# Cortex_M35P register map
Vendor: ARM Ltd.; Series: M
CPU: CM35 r0p0, little endian, vendor SysTick, 8 interrupt priority bits
Registers are 32-bit, read-write, no defined reset value unless marked. A register's access mark holds for its fields unless they carry their own. Offsets are from the block's base; [hi:lo] are bit positions; {n}, {i} and the like mark numbered series; 'fields as' and 'values as' point back to an identical list.

## ICB — Interrupt Control Registers
Base 0xE000E004
0x00 ICTR ro
  [3:0] INTLINESNUM
0x04 ACTLR
0x08 CPPWR
  [23] SUS11, [22] SU11, [21] SUS10, [20] SU10, [n] SUS{n} (n=0..7), [n] SU{n} (n=0..7)

## DCB — Debug Registers
Base 0xE000EDF0
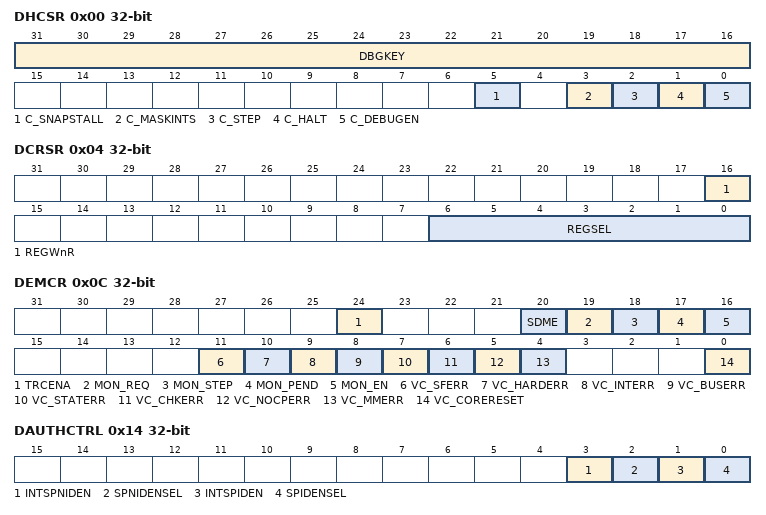
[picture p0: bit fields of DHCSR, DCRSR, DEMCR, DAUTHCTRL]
0x00 DHCSR
  [31:16] DBGKEY — Debug key
  [5] C_SNAPSTALL
  [3] C_MASKINTS
  [2] C_STEP
  [1] C_HALT
  [0] C_DEBUGEN
0x04 DCRSR wo
  [16] REGWnR, [6:0] REGSEL
0x08 DCRDR
  [31:0] DBGTMP
0x0C DEMCR ro
  [24] TRCENA, [20] SDME, [19] MON_REQ, [18] MON_STEP, [17] MON_PEND, [16] MON_EN, [11] VC_SFERR, [10] VC_HARDERR, [9] VC_INTERR, [8] VC_BUSERR, [7] VC_STATERR, [6] VC_CHKERR, [5] VC_NOCPERR, [4] VC_MMERR, [0] VC_CORERESET
0x14 DAUTHCTRL
  [3] INTSPNIDEN, [2] SPNIDENSEL, [1] INTSPIDEN, [0] SPIDENSEL
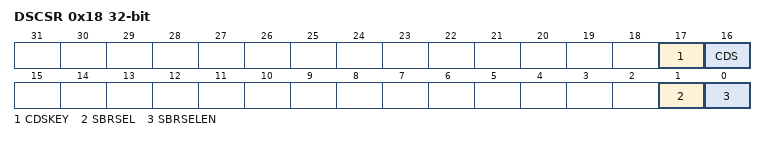
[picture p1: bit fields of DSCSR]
0x18 DSCSR ro
  [17] CDSKEY, [16] CDS, [1] SBRSEL, [0] SBRSELEN

## DIB — Identification Registers
Base 0xE000EFB0
0x00 DLAR wo
  [31:0] KEY
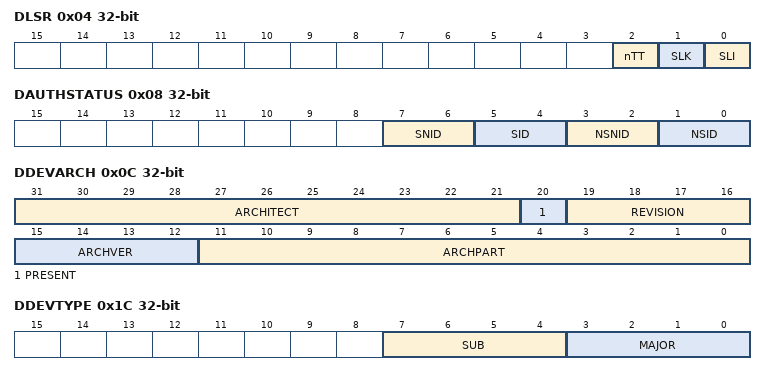
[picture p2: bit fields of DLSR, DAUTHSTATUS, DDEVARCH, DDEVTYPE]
0x04 DLSR ro
  [2] nTT, [1] SLK, [0] SLI
0x08 DAUTHSTATUS ro
  [7:6] SNID, [5:4] SID, [3:2] NSNID, [1:0] NSID
0x0C DDEVARCH ro
  [31:21] ARCHITECT, [20] PRESENT, [19:16] REVISION, [15:12] ARCHVER, [11:0] ARCHPART
0x1C DDEVTYPE ro
  [7:4] SUB — Sub-type
  [3:0] MAJOR
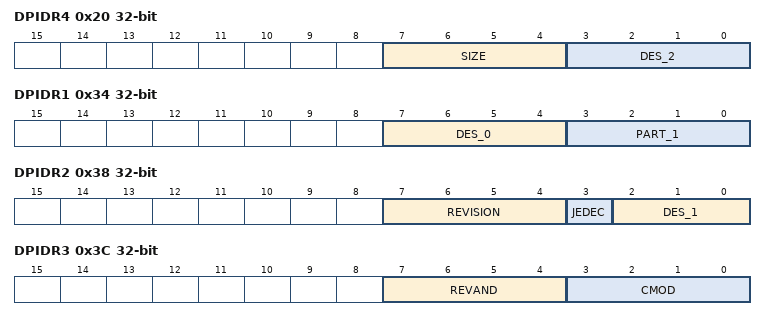
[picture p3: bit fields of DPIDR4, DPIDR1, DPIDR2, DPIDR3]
0x20 DPIDR4 ro
  [7:4] SIZE — 4KB count
  [3:0] DES_2
{0x10+4i} DPIDR{i} ro (i=5..7)
0x30 DPIDR0 ro
  [7:0] PART_0
0x34 DPIDR1 ro
  [7:4] DES_0, [3:0] PART_1
0x38 DPIDR2 ro
  [7:4] REVISION, [3] JEDEC, [2:0] DES_1
0x3C DPIDR3 ro
  [7:4] REVAND, [3:0] CMOD
0x40 DCIDR0 ro
  [7:0] PRMBL_0
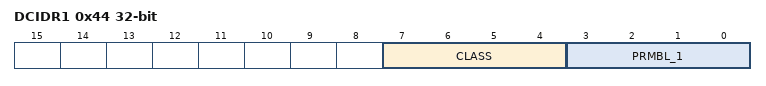
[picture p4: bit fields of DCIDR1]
0x44 DCIDR1 ro
  [7:4] CLASS, [3:0] PRMBL_1
0x48 DCIDR2 ro
  [7:0] PRMBL_2
0x4C DCIDR3 ro
  [7:0] PRMBL_3

## NVIC — Nested Vectored Interrupt Controller
Base 0xE000E100
0x00 NVIC_ISER{i} (i=0..15)
  [31:0] SETENA
0x00 NVIC_ISPR{i} (i=0..15)
  [31:0] SETPEND
0x80 NVIC_ICER{i} (i=0..15)
  [31:0] CLRENA
0x180 NVIC_ICPR{i} (i=0..15)
  [31:0] CLRPEND
0x200 NVIC_IABR{i} ro (i=0..15)
  [31:0] ACTIVE
0x280 NVIC_ITNS{i} (i=0..15)
  [31:0] ITNS
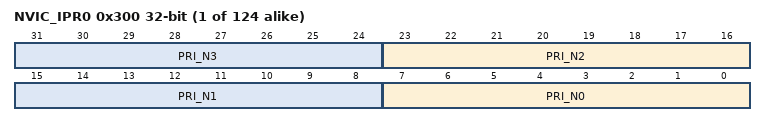
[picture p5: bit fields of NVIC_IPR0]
0x300 NVIC_IPR{i} (i=0..123)
  [8n+7:8n] PRI_N{n} (n=0..3)

## MPU — Memory protection Unit Control Registers
Base 0xE000ED90
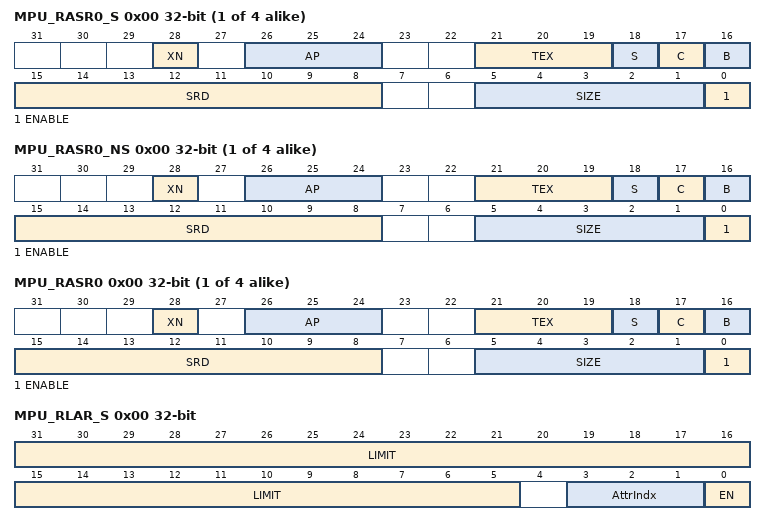
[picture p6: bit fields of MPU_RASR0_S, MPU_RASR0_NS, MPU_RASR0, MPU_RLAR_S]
0x00 MPU_RASR{i}_S (i=0..3)
  [28] XN, [26:24] AP, [21:19] TEX, [18] S, [17] C, [16] B, [15:8] SRD, [5:1] SIZE, [0] ENABLE
0x00 MPU_RASR{i}_NS (i=0..3)
  fields as MPU_RASR0_S
0x00 MPU_RASR{i} (i=0..3)
  fields as MPU_RASR0_S
0x00 MPU_RLAR_S
  [31:5] LIMIT
  [3:1] AttrIndx
  [0] EN — Enable
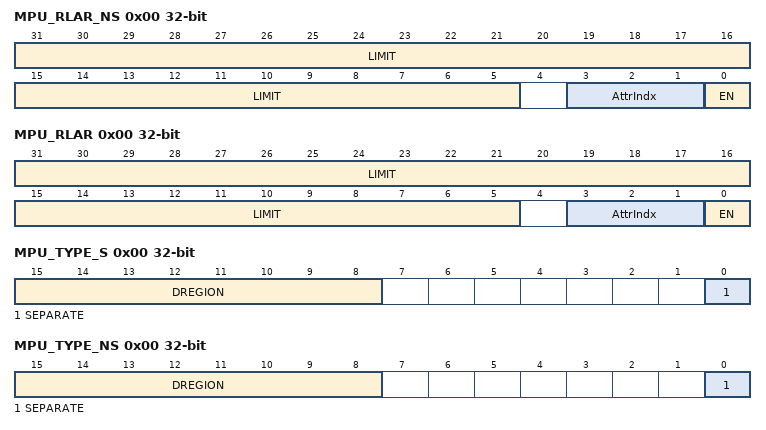
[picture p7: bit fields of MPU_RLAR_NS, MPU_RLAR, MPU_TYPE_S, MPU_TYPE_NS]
0x00 MPU_RLAR_NS
  [31:5] LIMIT
  [3:1] AttrIndx
  [0] EN — Enable
0x00 MPU_RLAR
  [31:5] LIMIT
  [3:1] AttrIndx
  [0] EN — Enable
0x00 MPU_TYPE_S ro
  [15:8] DREGION, [0] SEPARATE
0x00 MPU_TYPE_NS ro
  [15:8] DREGION, [0] SEPARATE
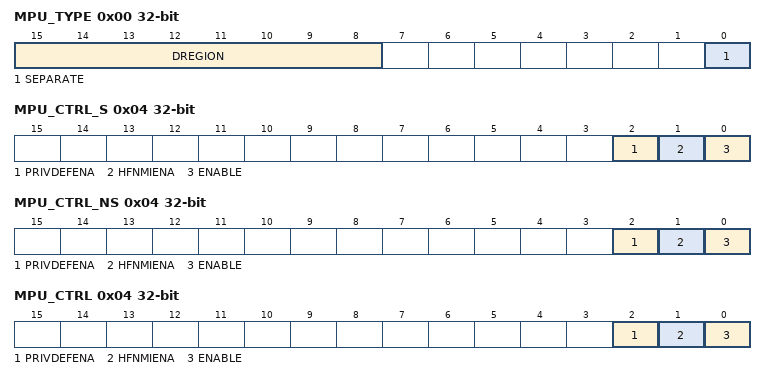
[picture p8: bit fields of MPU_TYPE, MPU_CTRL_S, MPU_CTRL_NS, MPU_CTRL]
0x00 MPU_TYPE ro
  [15:8] DREGION, [0] SEPARATE
0x04 MPU_CTRL_S
  [2] PRIVDEFENA, [1] HFNMIENA, [0] ENABLE
0x04 MPU_CTRL_NS
  [2] PRIVDEFENA, [1] HFNMIENA, [0] ENABLE
0x04 MPU_CTRL
  [2] PRIVDEFENA, [1] HFNMIENA, [0] ENABLE
0x08 MPU_RNR_S
  [7:0] REGION
0x08 MPU_RNR_NS
  [7:0] REGION
0x08 MPU_RNR
  [7:0] REGION
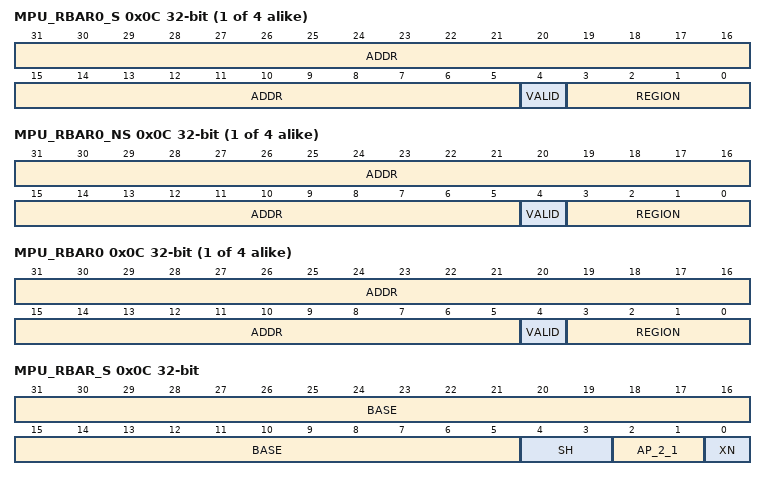
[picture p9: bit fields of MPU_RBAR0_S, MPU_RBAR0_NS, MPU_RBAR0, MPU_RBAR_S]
0x0C MPU_RBAR{i}_S (i=0..3)
  [31:5] ADDR, [4] VALID, [3:0] REGION
0x0C MPU_RBAR{i}_NS (i=0..3)
  [31:5] ADDR, [4] VALID, [3:0] REGION
0x0C MPU_RBAR{i} (i=0..3)
  [31:5] ADDR, [4] VALID, [3:0] REGION
0x0C MPU_RBAR_S
  [31:5] BASE, [4:3] SH, [2:1] AP_2_1, [0] XN
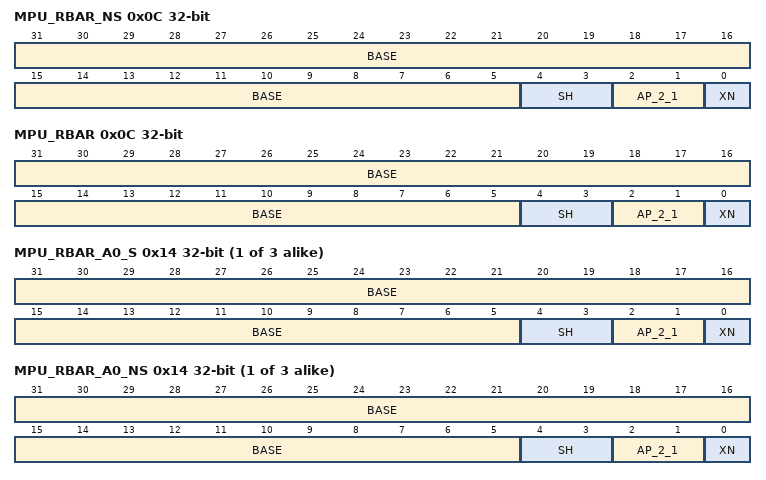
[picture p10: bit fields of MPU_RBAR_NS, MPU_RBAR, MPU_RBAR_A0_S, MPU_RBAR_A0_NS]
0x0C MPU_RBAR_NS
  [31:5] BASE, [4:3] SH, [2:1] AP_2_1, [0] XN
0x0C MPU_RBAR
  [31:5] BASE, [4:3] SH, [2:1] AP_2_1, [0] XN
0x14 MPU_RBAR_A{i}_S (i=0..2)
  [31:5] BASE, [4:3] SH, [2:1] AP_2_1, [0] XN
0x14 MPU_RBAR_A{i}_NS (i=0..2)
  [31:5] BASE, [4:3] SH, [2:1] AP_2_1, [0] XN
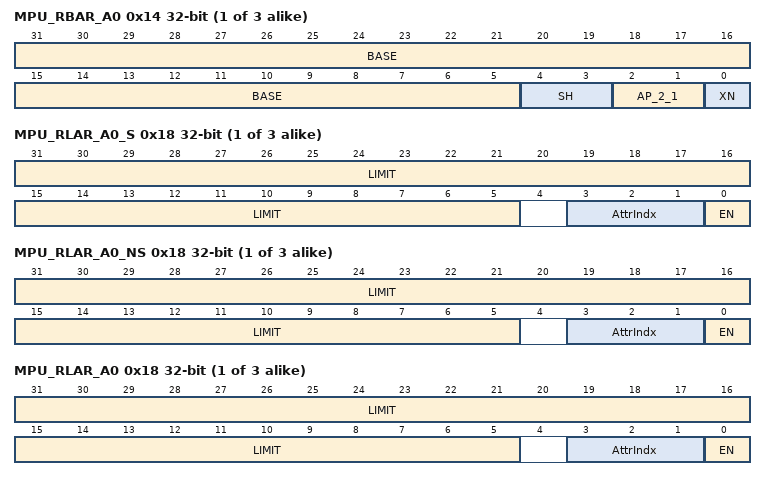
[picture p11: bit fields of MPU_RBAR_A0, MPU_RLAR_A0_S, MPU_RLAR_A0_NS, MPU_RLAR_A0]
0x14 MPU_RBAR_A{i} (i=0..2)
  [31:5] BASE, [4:3] SH, [2:1] AP_2_1, [0] XN
0x18 MPU_RLAR_A{i}_S (i=0..2)
  [31:5] LIMIT
  [3:1] AttrIndx
  [0] EN — Enable
0x18 MPU_RLAR_A{i}_NS (i=0..2)
  [31:5] LIMIT
  [3:1] AttrIndx
  [0] EN — Enable
0x18 MPU_RLAR_A{i} (i=0..2)
  [31:5] LIMIT
  [3:1] AttrIndx
  [0] EN — Enable
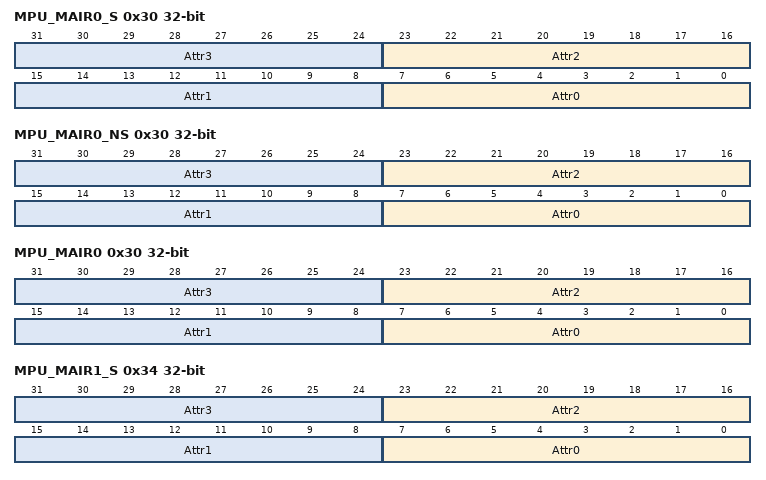
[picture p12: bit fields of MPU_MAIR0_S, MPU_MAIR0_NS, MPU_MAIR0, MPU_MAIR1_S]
0x30 MPU_MAIR0_S
  [8n+7:8n] Attr{n} (n=0..3)
0x30 MPU_MAIR0_NS
  [8n+7:8n] Attr{n} (n=0..3)
0x30 MPU_MAIR0
  [8n+7:8n] Attr{n} (n=0..3)
0x34 MPU_MAIR1_S
  [8n+7:8n] Attr{n} (n=0..3)
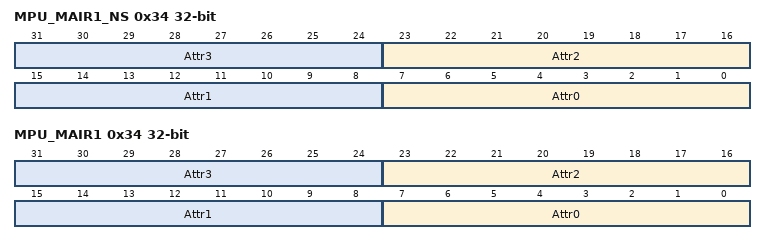
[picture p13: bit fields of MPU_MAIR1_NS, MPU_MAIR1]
0x34 MPU_MAIR1_NS
  [8n+7:8n] Attr{n} (n=0..3)
0x34 MPU_MAIR1
  [8n+7:8n] Attr{n} (n=0..3)

## SIG — Software Interrupt Control
Base 0xE000EF00
0x00 STIR wo
  [8:0] INTID

## SYST — SysTick Control Registers
Base 0xE000E010
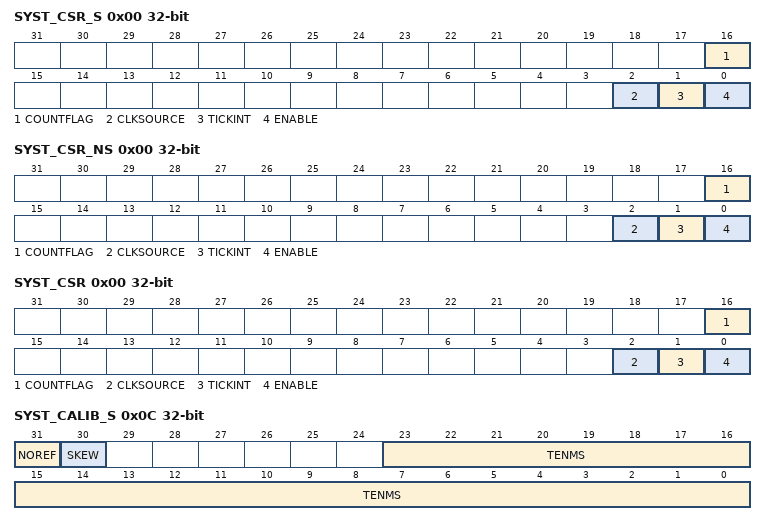
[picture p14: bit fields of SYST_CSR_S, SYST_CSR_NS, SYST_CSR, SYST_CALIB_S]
0x00 SYST_CSR_S
  [16] COUNTFLAG, [2] CLKSOURCE, [1] TICKINT, [0] ENABLE
0x00 SYST_CSR_NS
  [16] COUNTFLAG, [2] CLKSOURCE, [1] TICKINT, [0] ENABLE
0x00 SYST_CSR
  [16] COUNTFLAG, [2] CLKSOURCE, [1] TICKINT, [0] ENABLE
0x04 SYST_RVR_S
  [23:0] RELOAD
0x04 SYST_RVR_NS
  [23:0] RELOAD
0x04 SYST_RVR
  [23:0] RELOAD
0x08 SYST_CVR_S
  [23:0] CURRENT
0x08 SYST_CVR_NS
  [23:0] CURRENT
0x08 SYST_CVR
  [23:0] CURRENT
0x0C SYST_CALIB_S ro
  [31] NOREF, [30] SKEW, [23:0] TENMS
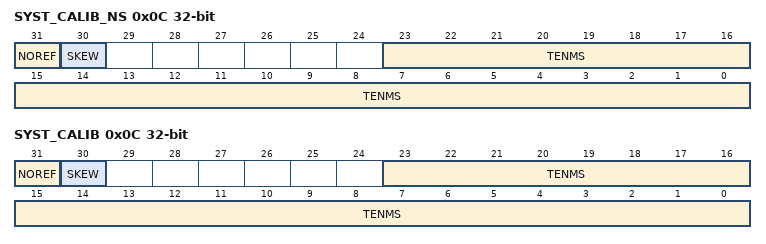
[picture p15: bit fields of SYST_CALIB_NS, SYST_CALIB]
0x0C SYST_CALIB_NS ro
  [31] NOREF, [30] SKEW, [23:0] TENMS
0x0C SYST_CALIB ro
  [31] NOREF, [30] SKEW, [23:0] TENMS

## SAU — Security Attribute Unit
Base 0xE000EDD0
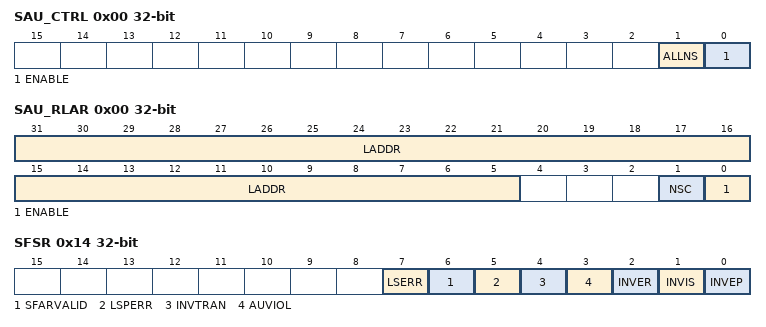
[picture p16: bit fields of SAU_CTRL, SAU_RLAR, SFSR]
0x00 SAU_CTRL
  [1] ALLNS, [0] ENABLE
0x00 SAU_RLAR
  [31:5] LADDR, [1] NSC, [0] ENABLE
0x04 SAU_TYPE ro
  [7:0] SREGION
0x08 SAU_RNR
  [7:0] REGION
0x0C SAU_RBAR
  [31:5] BADDR
0x14 SFSR
  [7] LSERR, [6] SFARVALID, [5] LSPERR, [4] INVTRAN, [3] AUVIOL, [2] INVER, [1] INVIS, [0] INVEP
0x18 SFAR
  [31:0] ADDRESS
